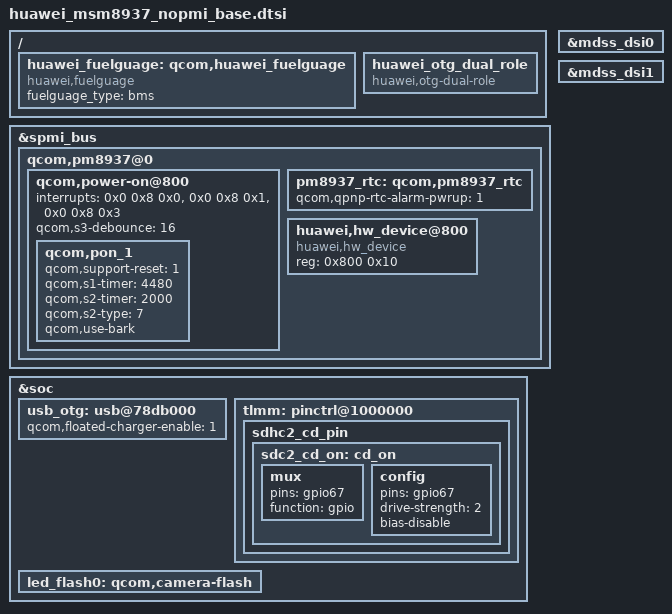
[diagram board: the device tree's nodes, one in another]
/*=============================================================================
                           Huawei Base Dtsi File
  GENERAL DESCRIPTION
    This file is for include the Communal node

  Copyright 2010-2014 by HUAWEI Technologies, Inc.  All Rights Reserved.
=============================================================================*/
#include "msm8937.dtsi"
#include "msm8937-pmi8940-mtp.dtsi"

&spmi_bus {

	qcom,pm8937@0 {
		qcom,power-on@800 {
			interrupts = <0x0 0x8 0x0>,
				<0x0 0x8 0x1>,
				<0x0 0x8 0x3>;
			interrupt-names = "kpdpwr", "resin","kpdpwr-bark";
			qcom,s3-debounce = <16>;

			qcom,pon_1 {
				qcom,support-reset = <1>;
				qcom,s1-timer = <4480>;
				qcom,s2-timer = <2000>;
				qcom,s2-type = <7>;
				qcom,use-bark;
			};
		};
		pm8937_rtc: qcom,pm8937_rtc {
			qcom,qpnp-rtc-alarm-pwrup = <1>;
		};
		huawei,hw_device@800 {
			compatible = "huawei,hw_device";
			reg = <0x800 0x10>;
		};
	};
};

/{
	huawei_fuelguage: qcom,huawei_fuelguage{
		compatible = "huawei,fuelguage";
		fuelguage_type = "bms";
		status = "okay";
	};
};
/ {
	huawei_otg_dual_role:huawei_otg_dual_role{
		compatible = "huawei,otg-dual-role";
		status = "okay";
	};
};

&soc {
	usb_otg: usb@78db000 {
		qcom,floated-charger-enable = <1>;
	};

	tlmm: pinctrl@1000000 {
		sdhc2_cd_pin {
			sdc2_cd_on: cd_on {
				mux {
					pins = "gpio67";
					function = "gpio";
				};

				config {
					pins = "gpio67";
					drive-strength = <2>;
					bias-disable;
				};
		   };
		};
	};
};

&soc {
	led_flash0: qcom,camera-flash {
		/delete-property/qcom,flash-source;
		/delete-property/qcom,torch-source;
		/delete-property/qcom,switch-source;
	};
};

&mdss_dsi0 {
	/delete-property/lab-supply;
	/delete-property/ibb-supply;
};

&mdss_dsi1 {
	/delete-property/lab-supply;
	/delete-property/ibb-supply;
};
